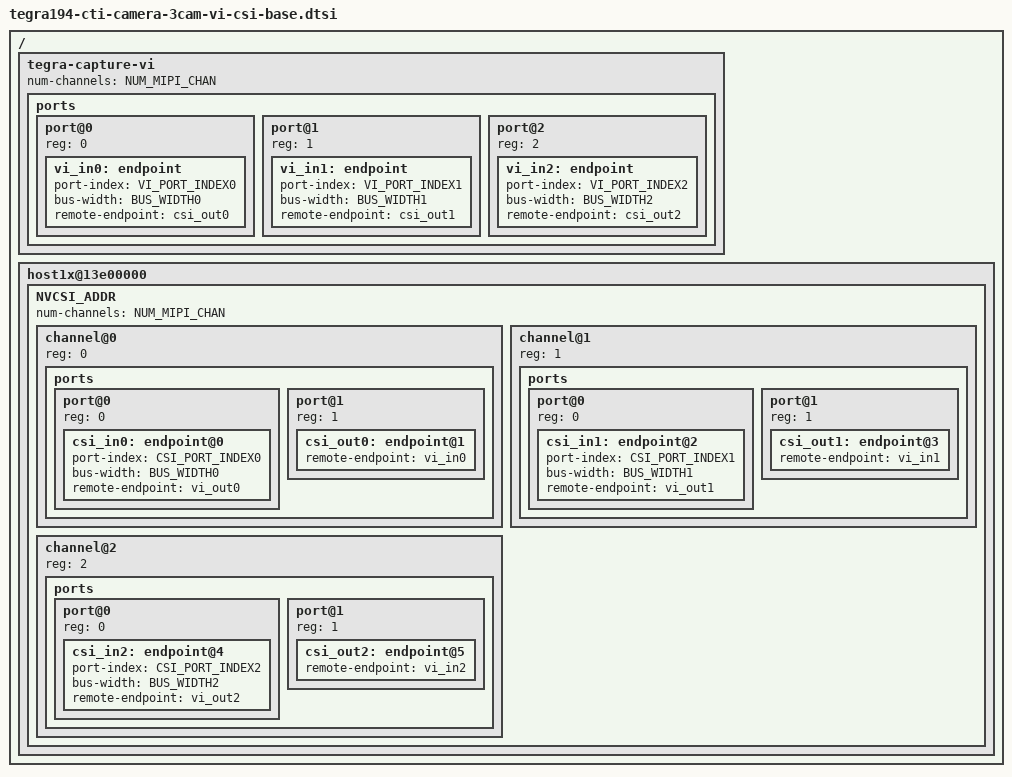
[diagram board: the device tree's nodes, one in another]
/ {
		tegra-capture-vi{
			num-channels = <NUM_MIPI_CHAN>;
			status = "okay";
			ports {
				#address-cells = <1>;
				#size-cells = <0>;
				port@0 {
					reg = <0>;
					status = "okay";
					vi_in0: endpoint {
						//vc-id = <0>;
						port-index = <VI_PORT_INDEX0>;
						bus-width = <BUS_WIDTH0>;
						status = "okay";
						remote-endpoint = <&csi_out0>;
					};
				};
				port@1 {
					reg = <1>;
					status = "okay";
					vi_in1: endpoint {
						//vc-id = <1>;
						port-index = <VI_PORT_INDEX1>;
						bus-width = <BUS_WIDTH1>;
						status = "okay";
						remote-endpoint = <&csi_out1>;
					};
				};
				port@2 {
					reg = <2>;
					status = "okay";
					vi_in2: endpoint {
						//vc-id = <0>;
						port-index = <VI_PORT_INDEX2>;
						bus-width = <BUS_WIDTH2>;
						status = "okay";
						remote-endpoint = <&csi_out2>;
					};
				};
			};
		};
	
	host1x@13e00000{
		NVCSI_ADDR {
			num-channels = <NUM_MIPI_CHAN>;
			#address-cells = <1>;
			#size-cells = <0>;
			status = "okay";	
			channel@0 {
				reg = <0>;
				status = "okay";	
				ports {
					#address-cells = <1>;
					#size-cells = <0>;
					port@0 {
						reg = <0>;
						status = "okay";
						csi_in0: endpoint@0 {
							port-index = <CSI_PORT_INDEX0>;
							bus-width = <BUS_WIDTH0>;
							status = "okay";
							remote-endpoint = <&vi_out0>;
						};
					};
					port@1 {
						reg = <1>;
						status = "okay";
						csi_out0: endpoint@1 {
							remote-endpoint = <&vi_in0>;
							status = "okay";
						};
					};
				};
			};
			channel@1 {
				reg = <1>;
				status = "okay";	
				ports {
					#address-cells = <1>;
					#size-cells = <0>;
					port@0 {
						reg = <0>;
						status = "okay";
						csi_in1: endpoint@2 {
							port-index = <CSI_PORT_INDEX1>;
							bus-width = <BUS_WIDTH1>;
							status = "okay";
							remote-endpoint = <&vi_out1>;
						};
					};
					port@1 {
						reg = <1>;
						status = "okay";
						csi_out1: endpoint@3 {
							remote-endpoint = <&vi_in1>;
							status = "okay";
						};
					};
				};
			};
			channel@2 {
				reg = <2>;
				status = "okay";	
				ports {
					#address-cells = <1>;
					#size-cells = <0>;
					port@0 {
						reg = <0>;
						status = "okay";	
						csi_in2: endpoint@4 {
							port-index = <CSI_PORT_INDEX2>;
							bus-width = <BUS_WIDTH2>;
							status = "okay";
							remote-endpoint = <&vi_out2>;
						};
					};
					port@1 {
						reg = <1>;
						status = "okay";	
						csi_out2: endpoint@5 {
							remote-endpoint = <&vi_in2>;
							status = "okay";
						};
					};
				};
			};
		};
	};
};
